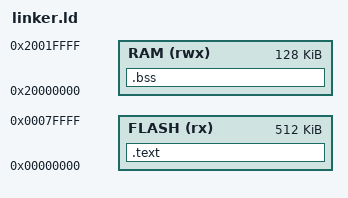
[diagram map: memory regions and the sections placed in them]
MEMORY
{
    FLASH (rx)  : ORIGIN = 0x00000000, LENGTH = 512K
    RAM   (rwx) : ORIGIN = 0x20000000, LENGTH = 128K
}

_stack_top = ORIGIN(RAM) + LENGTH(RAM);

SECTIONS
{
    .text :
    {
        KEEP(*(.vectors))
        *(.text*)
        *(.rodata*)
    } > FLASH

    .bss :
    {
        _bss_start = .;
        *(.bss*)
        _bss_end = .;
    } > RAM
}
